# EFR32FG2DB020F512IM48 register map
Vendor: Silicon Labs; Series: EFR32; File version: A
Registers are 32-bit, read-write, reset 0x0 unless marked. A register's access mark holds for its fields unless they carry their own. Offsets are from the block's base; [hi:lo] are bit positions; {n}, {i} and the like mark numbered series.

## PFMXPPRF_NS — PFMXPPRF_NS Registers
Base 0x500C4000
Same registers: PFMXPPRF_S 0x400C4000
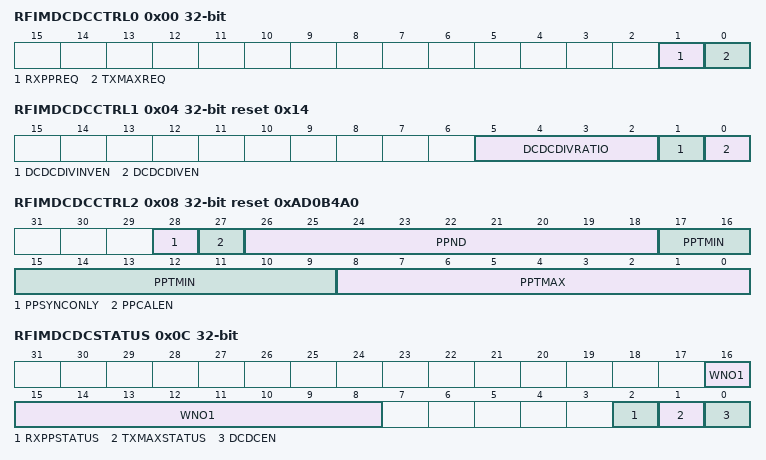
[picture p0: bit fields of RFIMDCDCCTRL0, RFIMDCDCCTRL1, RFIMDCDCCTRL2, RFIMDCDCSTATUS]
0x00 RFIMDCDCCTRL0
  [1] RXPPREQ, [0] TXMAXREQ
0x04 RFIMDCDCCTRL1 reset 0x14
  [5:2] DCDCDIVRATIO
    0=DIVRATIO8 (Dividing master_rf clk by 8, D=50%); 1=DIVRATIO9 (Dividing master_rf clk by 9, D=44.4%); 2=DIVRATIO10 (Dividing master_rf clk by 10, D=40%); 3=DIVRATIO11 (Dividing master_rf clk by 11, D=36.4%); 4=DIVRATIO12 (Dividing master_rf clk by 12, D=50%); 5=DIVRATIO13 (Dividing master_rf clk by 13, D=46.2%); 6=DIVRATIO14 (Dividing master_rf clk by 14, D=42.9%); 7=DIVRATIO15 (Dividing master_rf clk by 15, D=40%); 8=DIVRATIO16 (Dividing master_rf clk by 16, D=50%); 9=DIVRATIO17 (Dividing master_rf clk by 17, D=47.1%); 10=DIVRATIO18 (Dividing master_rf clk by 18, D=44.4%); 11=DIVRATIO19 (Dividing master_rf clk by 19, D=42.1%); 12=DIVRATIO20 (Dividing master_rf clk by 20, D=60%); 13=DIVRATIO21 (Dividing master_rf clk by 21, D=57.1%); 14=DIVRATIO22 (Dividing master_rf clk by 22, D=54.5%); 15=DIVRATIO23 (Dividing master_rf clk by 23, D=52.2%)
  [1] DCDCDIVINVEN — DCDC DIV Inverter Enable
  [0] DCDCDIVEN — DCDC DIV Enable
0x08 RFIMDCDCCTRL2 reset 0xAD0B4A0
  [28] PPSYNCONLY — Pulse Pairing Sync Only
  [27] PPCALEN — Pulse Pairing Calibration Loop Enable
  [26:18] PPND — Pulse Pairing Period
  [17:9] PPTMIN — Pulse Pairing Time Min
  [8:0] PPTMAX — Pulse Pairing Time Max
0x0C RFIMDCDCSTATUS ro
  [16:8] WNO1 — Cal Loop WNO1 value
  [2] RXPPSTATUS
  [1] TXMAXSTATUS
  [0] DCDCEN — DCDC Enable Status
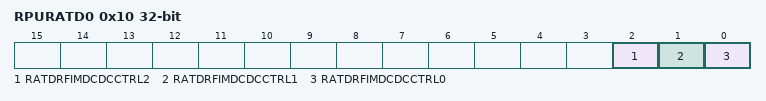
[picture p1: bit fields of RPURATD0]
0x10 RPURATD0 — Protected register address = (RPURATD register index X 32 + RPURATD bit index) X 4.
  [2] RATDRFIMDCDCCTRL2 — RFIMDCDCCTRL2 Protection Bit
  [1] RATDRFIMDCDCCTRL1 — RFIMDCDCCTRL1 Protection Bit
  [0] RATDRFIMDCDCCTRL0 — RFIMDCDCCTRL0 Protection Bit

## SCRATCHPAD_NS — SCRATCHPAD_NS Registers
Base 0x50000000
Same registers: SCRATCHPAD_S 0x40000000
0x00 SREG0 — Used for SIMCTRL Pointer in Verification Environment
  [31:0] SCRATCH — Scratch Pad Register
0x04 SREG1 — Used for SIMCTRL Data Access in Verification Environment
  [31:0] SCRATCH

## SEMAILBOX_NS_HOST — SEMAILBOX_NS_HOST Registers
Base 0x5C000000
Same registers: SEMAILBOX_S_HOST 0x4C000000
0x00 FIFO — A write access to any address in this area will be mapped to the TX FIFO (only for the payload). A read access to any address in this area will be mapped to the RX FIFO (only for the payload). Using an address range (16 x 32-bit) rather than one single address mapped to the FIFO allows using incremental bursts.
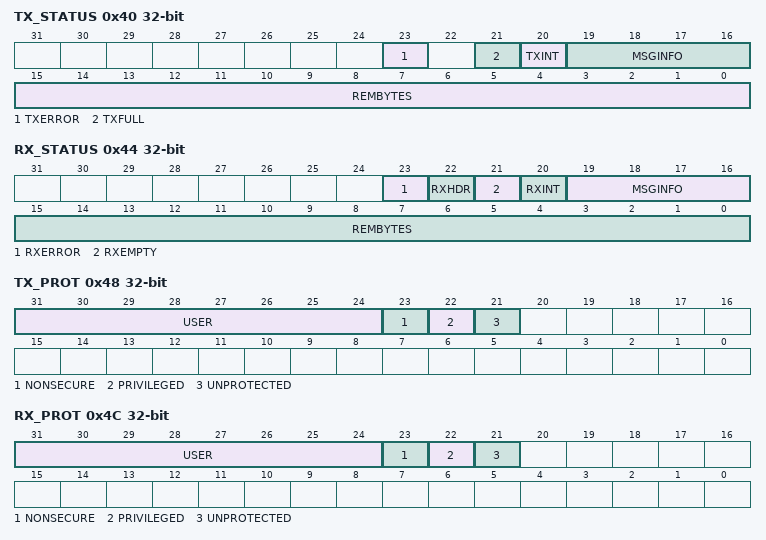
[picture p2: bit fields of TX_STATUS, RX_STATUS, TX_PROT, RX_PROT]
0x40 TX_STATUS ro
  [23] TXERROR, [21] TXFULL, [20] TXINT, [19:16] MSGINFO, [15:0] REMBYTES
0x44 RX_STATUS ro
  [23] RXERROR, [22] RXHDR, [21] RXEMPTY, [20] RXINT, [19:16] MSGINFO, [15:0] REMBYTES
0x48 TX_PROT ro — TX Protection register.
  [31:24] USER, [23] NONSECURE, [22] PRIVILEGED, [21] UNPROTECTED
0x4C RX_PROT ro — RX Protection register.
  [31:24] USER, [23] NONSECURE, [22] PRIVILEGED, [21] UNPROTECTED
0x50 TX_HEADER wo — A write access to this register will be mapped to the TX FIFO (only for header).
  [31:0] TXHEADER
0x54 RX_HEADER ro — A read access to this register will be mapped to the RX FIFO (only for the header).
  [31:0] RXHEADER
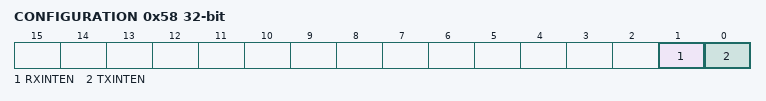
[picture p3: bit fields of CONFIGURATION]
0x58 CONFIGURATION
  [1] RXINTEN, [0] TXINTEN

## SMU_NS_CFGNS — SMU_NS_CFGNS Registers
Base 0x5400C000
Same registers: SMU_S_CFGNS 0x4400C000
0x04 NSSTATUS ro
  [0] SMUNSLOCK — SMUNS Lock Status
    0=UNLOCKED (SMUNSLOCK is Unlocked); 1=LOCKED (SMUNSLOCK is Locked)
0x08 NSLOCK wo
  [23:0] SMUNSLOCKKEY — SMU Non-Secure Lock/Key
    0xACCE55=UNLOCK (Unlocks Registers)
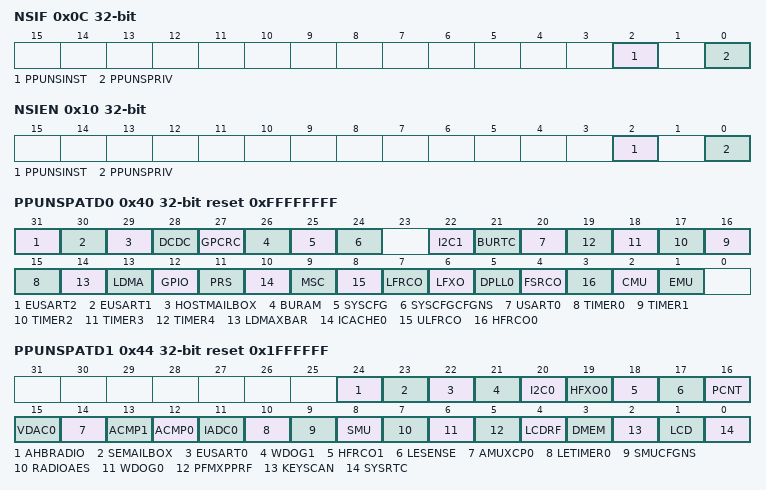
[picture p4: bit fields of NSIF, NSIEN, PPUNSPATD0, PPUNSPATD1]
0x0C NSIF
  [2] PPUNSINST — PPUNS Instruction Interrupt Flag
  [0] PPUNSPRIV — PPUNS Privilege Interrupt Flag
0x10 NSIEN
  [2] PPUNSINST — PPUNS Instruction Interrupt Enable
  [0] PPUNSPRIV — PPUNS Privilege Interrupt Enable
0x40 PPUNSPATD0 reset 0xFFFFFFFF — Set peripheral bits to 1 to mark as privileged access only
  [31] EUSART2 — EUSART2 Privileged Access
  [30] EUSART1 — EUSART1 Privileged Access
  [29] HOSTMAILBOX — HOSTMAILBOX Privileged Access
  [28] DCDC — DCDC Privileged Access
  [27] GPCRC — GPCRC Privileged Access
  [26] BURAM — BURAM Privileged Access
  [25] SYSCFG — SYSCFG Privileged Access
  [24] SYSCFGCFGNS — SYSCFGCFGNS Privileged Access
  [22] I2C1 — I2C1 Privileged Access
  [21] BURTC — BURTC Privileged Access
  [20] USART0 — USART0 Privileged Access
  [n+15] TIMER{n} (n=0..4) — TIMER{n} Privileged Access
  [14] LDMAXBAR — LDMAXBAR Privileged Access
  [13] LDMA — LDMA Privileged Access
  [12] GPIO — GPIO Privileged Access
  [11] PRS — PRS Privileged Access
  [10] ICACHE0 — ICACHE0 Privileged Access
  [9] MSC — MSC Privileged Access
  [8] ULFRCO — ULFRCO Privileged Access
  [7] LFRCO — LFRCO Privileged Access
  [6] LFXO — LFXO Privileged Access
  [5] DPLL0 — DPLL0 Privileged Access
  [4] FSRCO — FSRCO Privileged Access
  [3] HFRCO0 — HFRCO0 Privileged Access
  [2] CMU — CMU Privileged Access
  [1] EMU — EMU Privileged Access
0x44 PPUNSPATD1 reset 0x1FFFFFF — Set peripheral bits to 1 to mark as privileged access only
  [24] AHBRADIO — AHBRADIO Privileged Access
  [23] SEMAILBOX — SEMAILBOX Privileged Access
  [22] EUSART0 — EUSART0 Privileged Access
  [21] WDOG1 — WDOG1 Privileged Access
  [20] I2C0 — I2C0 Privileged Access
  [19] HFXO0 — HFXO0 Privileged Access
  [18] HFRCO1 — HFRCO1 Privileged Access
  [17] LESENSE — LESENSE Privileged Access
  [16] PCNT — PCNT Privileged Access
  [15] VDAC0 — VDAC0 Privileged Access
  [14] AMUXCP0 — AMUXCP0 Privileged Access
  [13] ACMP1 — ACMP1 Privileged Access
  [12] ACMP0 — ACMP0 Privileged Access
  [11] IADC0 — IADC0 Privileged Access
  [10] LETIMER0 — LETIMER0 Privileged Access
  [9] SMUCFGNS — SMUCFGNS Privileged Access
  [8] SMU — SMU Privileged Access
  [7] RADIOAES — RADIOAES Privileged Access
  [6] WDOG0 — WDOG0 Privileged Access
  [5] PFMXPPRF — PFMXPPRF Privileged Access
  [4] LCDRF — LCDRF Privileged Access
  [3] DMEM — DMEM Privileged Access
  [2] KEYSCAN — KEYSCAN Privileged Access
  [1] LCD — LCD Privileged Access
  [0] SYSRTC — SYSRTC Privileged Access
0x140 PPUNSFS ro
  [7:0] PPUFSPERIPHID — Peripheral I
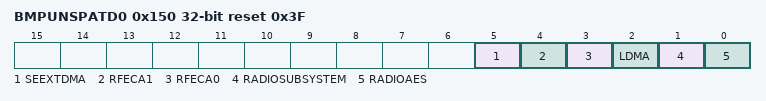
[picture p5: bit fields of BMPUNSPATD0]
0x150 BMPUNSPATD0 reset 0x3F
  [5] SEEXTDMA — SEEXTDMA Privileged Mode
  [4] RFECA1 — RFECA1 Privileged Mode
  [3] RFECA0 — RFECA0 Privileged Mode
  [2] LDMA — LDMA Privileged Mode
  [1] RADIOSUBSYSTEM — RADIOSUBSYSTEM Privileged Mode
  [0] RADIOAES — RADIOAES Privileged Mode
